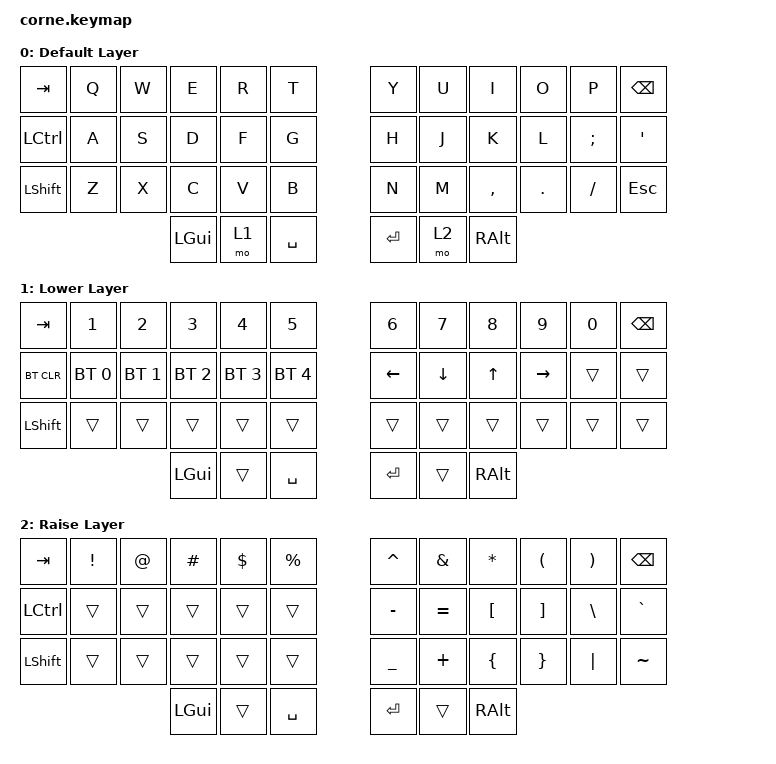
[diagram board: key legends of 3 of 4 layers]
/*
 * Copyright (c) 2020 The ZMK Contributors
 *
 * SPDX-License-Identifier: MIT
 */

#include <behaviors.dtsi>
#include <dt-bindings/zmk/keys.h>
#include <dt-bindings/zmk/bt.h>
#include <dt-bindings/zmk/rgb.h>

&led_strip {
    chain-length = <27>;
};

/ {
    keymap {
        compatible = "zmk,keymap";

        default_layer {
            display-name = "Default Layer";
            bindings = <
                &kp TAB   &kp Q &kp W &kp E &kp R &kp T   &kp Y &kp U  &kp I     &kp O   &kp P    &kp BSPC
                &kp LCTRL &kp A &kp S &kp D &kp F &kp G   &kp H &kp J  &kp K     &kp L   &kp SEMI &kp SQT
                &kp LSHFT &kp Z &kp X &kp C &kp V &kp B   &kp N &kp M  &kp COMMA &kp DOT &kp FSLH &kp ESC
                  &kp LGUI &mo 1 &kp SPACE   &kp RET &mo 2 &kp RALT
            >;
        };
        lower_layer {
            display-name = "Lower Layer";
            bindings = <
                &kp TAB    &kp N1       &kp N2       &kp N3       &kp N4       &kp N5         &kp N6   &kp N7   &kp N8 &kp N9    &kp N0 &kp BSPC
                &bt BT_CLR &bt BT_SEL 0 &bt BT_SEL 1 &bt BT_SEL 2 &bt BT_SEL 3 &bt BT_SEL 4   &kp LEFT &kp DOWN &kp UP &kp RIGHT &trans &trans
                &kp LSHFT  &trans       &trans       &trans       &trans       &trans         &trans   &trans   &trans &trans    &trans &trans
                    &kp LGUI     &trans       &kp SPACE      &kp RET  &trans   &kp RALT
            >;
        };

        raise_layer {
            display-name = "Raise Layer";
            bindings = <
                &kp  TAB  &kp EXCL &kp AT &kp HASH &kp DLLR &kp PRCNT   &kp CARET &kp AMPS  &kp ASTRK &kp LPAR &kp RPAR &kp BSPC
                &kp LCTRL &trans   &trans &trans   &trans   &trans      &kp MINUS &kp EQUAL &kp LBKT  &kp RBKT &kp BSLH &kp GRAVE
                &kp LSHFT &trans   &trans &trans   &trans   &trans      &kp UNDER &kp PLUS  &kp LBRC  &kp RBRC &kp PIPE &kp TILDE
                             &kp LGUI &trans   &kp SPACE   &kp RET   &trans    &kp RALT
            >;
        };

        rgb_layer {
            display-name = "RGB";
            bindings = <
                &rgb_ug RGB_TOG &rgb_ug RGB_EFF &rgb_ug RGB_EFR &rgb_ug RGB_ON &rgb_ug RGB_OFF &trans
                &rgb_ug RGB_BRI &rgb_ug RGB_BRD &rgb_ug RGB_SPI &rgb_ug RGB_SPD &trans &trans
                &rgb_ug RGB_HUI &rgb_ug RGB_HUD &rgb_ug RGB_SAI &rgb_ug RGB_SAD &trans &trans
                &trans &trans &trans &trans &trans &trans
            >;
        };

    };

    combos {
        compatible = "zmk,combos";
        combo_rgb_layer {
            timeout-ms = <50>;
            key-positions = <37 40>; // Lower (37) e Raise (40)
            layers = <0>;
            bindings = <&mo 3>;      // Ativa sua camada RGB (se RGB for outra camada, troque o número)
        };
    };
};
